# STM32C071 register map
File version: 1.1
CPU: CM0+ r0p0, little endian, MPU, no FPU, 2 interrupt priority bits
Registers are 32-bit, read-write, reset 0x0 unless marked. A register's access mark holds for its fields unless they carry their own. Offsets are from the block's base; [hi:lo] are bit positions; {n}, {i} and the like mark numbered series.

## DBG — DBG address block description
Base 0x40015800
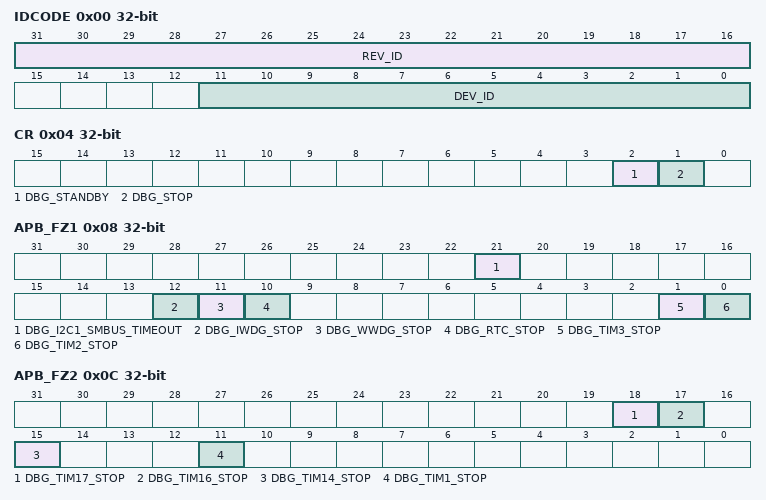
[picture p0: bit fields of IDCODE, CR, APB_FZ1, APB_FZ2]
0x00 IDCODE ro reset not defined — DBG device ID code register
  [31:16] REV_ID — Revision identifier This field indicates the revision of the device. Refer to Table 152.
  [11:0] DEV_ID — Device identifier This field indicates the device ID. Refer to Table 152.
0x04 CR — DBG configuration register
  [2] DBG_STANDBY — Debug Standby and Shutdown modes Debug options in Standby or Shutdown mode.
  [1] DBG_STOP — Debug Stop mode Debug options in Stop mode. Upon Stop mode exit, the software must re-establish the desired clock configuration.
0x08 APB_FZ1 — DBG APB freeze register 1
  [21] DBG_I2C1_SMBUS_TIMEOUT — SMBUS timeout when core is halted
  [12] DBG_IWDG_STOP — Clocking of IWDG counter when the core is halted This bit enables/disables the clock to the counter of IWDG when the core is halted:
  [11] DBG_WWDG_STOP — Clocking of WWDG counter when the core is halted This bit enables/disables the clock to the counter of WWDG when the core is halted:
  [10] DBG_RTC_STOP — Clocking of RTC counter when the core is halted This bit enables/disables the clock to the counter of RTC when the core is halted:
  [1] DBG_TIM3_STOP — Clocking of TIM3 counter when the core is halted This bit enables/disables the clock to the counter of TIM3 when the core is halted:
  [0] DBG_TIM2_STOP — Clocking of TIM2 counter when the core is halted This bit enables/disables the clock to the counter of TIM2 when the core is halted: This bit is only available on STM32C071xx. On the other devices, it is reserved.
0x0C APB_FZ2 — DBG APB freeze register 2
  [18] DBG_TIM17_STOP — Clocking of TIM17 counter when the core is halted This bit enables/disables the clock to the counter of TIM17 when the core is halted:
  [17] DBG_TIM16_STOP — Clocking of TIM16 counter when the core is halted This bit enables/disables the clock to the counter of TIM16 when the core is halted:
  [15] DBG_TIM14_STOP — Clocking of TIM14 counter when the core is halted This bit enables/disables the clock to the counter of TIM14 when the core is halted:
  [11] DBG_TIM1_STOP — Clocking of TIM1 counter when the core is halted This bit enables/disables the clock to the counter of TIM1 when the core is halted:

## DMAMUX — DMAMUX address block description
Base 0x40020800
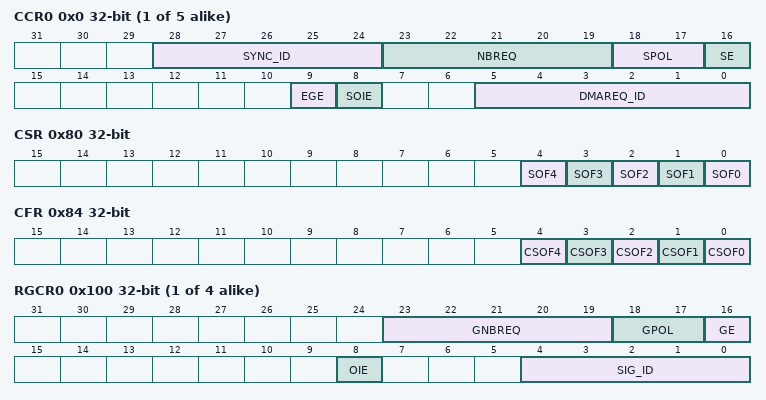
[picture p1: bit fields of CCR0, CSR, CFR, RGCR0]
{0x0+4i} CCR{i} (i=0..4) — DMA Multiplexer Channel {i} Control register
  [28:24] SYNC_ID — Synchronization identification Selects the synchronization input (see Table 44: DMAMUX: assignment of synchronization inputs to resources).
  [23:19] NBREQ — Number of DMA requests minus 1 to forward Defines the number of DMA requests to forward to the DMA controller after a synchronization event, and/or the number of DMA requests before an output event is generated. This field must only be written when both SE and EGE bits are low.
  [18:17] SPOL — Synchronization polarity Defines the edge polarity of the selected synchronization input:
    0=NoEdge (No event, i.e. no synchronization nor detection); 1=RisingEdge; 2=FallingEdge; 3=BothEdges (Rising and falling edges)
  [16] SE — Synchronization enable
    0=Disabled (Synchronization disabled); 1=Enabled (Synchronization enabled)
  [9] EGE — Event generation enable
    0=Disabled (Event generation disabled); 1=Enabled (Event generation enabled)
  [8] SOIE — Synchronization overrun interrupt enable
    0=Disabled (Synchronization overrun interrupt disabled); 1=Enabled (Synchronization overrun interrupt enabled)
  [5:0] DMAREQ_ID — DMA request identification Selects the input DMA request. See the DMAMUX table about assignments of multiplexer inputs to resources.
0x80 CSR ro — DMAMUX request line multiplexer interrupt channel status register
  [n] SOF{n} (n=0..4) — Synchronization Overrun Flag {n}
    0=NoSyncEvent (No synchronization event occured on a DMA request line multiplexer channel x, while the DMA request counter value is lower than NBREQ); 1=SyncEvent (Synchronization event occured on a DMA request line multiplexer channel x, while the DMA request counter value is lower than NBREQ)
0x84 CFR wo — DMAMUX request line multiplexer interrupt clear flag register
  [n] CSOF{n} (n=0..4) write-1-clears — Synchronization Clear Overrun Flag {n}
    1=Clear synchronization flag
{0x100+4i} RGCR{i} (i=0..3) — DMAMUX request generator channel {i} configuration register
  [23:19] GNBREQ — Number of DMA requests to be generated (minus 1) Defines the number of DMA requests to be generated after a trigger event. The actual number of generated DMA requests is GNBREQ +1. Note: This field must be written only when GE bit is disabled.
  [18:17] GPOL — DMA request generator trigger polarity Defines the edge polarity of the selected trigger input
    0=NoEdge (No event, i.e. no detection nor generation); 1=RisingEdge; 2=FallingEdge; 3=BothEdges (Rising and falling edges)
  [16] GE — DMA request generator channel x enable
    0=Disabled (DMA request generation disabled); 1=Enabled (DMA request enabled)
  [8] OIE — Trigger overrun interrupt enable
    0=Disabled (Trigger overrun interrupt disabled); 1=Enabled (Trigger overrun interrupt enabled)
  [4:0] SIG_ID — Signal identification Selects the DMA request trigger input used for the channel x of the DMA request generator
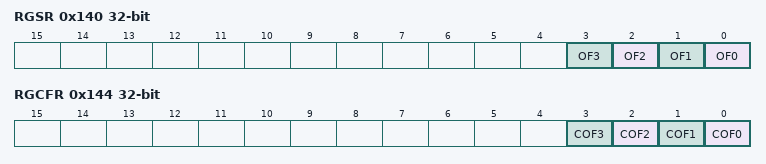
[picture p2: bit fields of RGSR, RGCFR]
0x140 RGSR ro — DMAMUX request generator interrupt status register
  [n] OF{n} (n=0..3) — Generator Overrun Flag {n}
    0=NoTrigger (No new trigger event occured on DMA request generator channel x, before the request counter underrun); 1=Trigger (New trigger event occured on DMA request generator channel x, before the request counter underrun)
0x144 RGCFR wo — DMAMUX request generator interrupt clear flag register
  [n] COF{n} (n=0..3) write-1-clears — Generator Clear Overrun Flag {n}
    1=Clear overrun flag
